# ATSAM4CMS32C_0 register map
Vendor: Atmel; Series: SAM4CM; File version: 0
CPU: CM4 r0p0, selectable endian, MPU, no FPU, 4 interrupt priority bits
Registers are 32-bit, read-write, reset 0x0 unless marked. A register's access mark holds for its fields unless they carry their own. Offsets are from the block's base; [hi:lo] are bit positions; {n}, {i} and the like mark numbered series.

## TRNG — True Random Number Generator
Base 0x40048000; register names take the prefix TRNG_
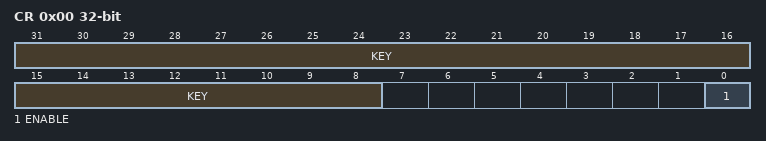
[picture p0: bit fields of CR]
0x00 CR wo reset not defined — Control Register
  [31:8] KEY — Security Key.
    0x524E47=PASSWD (Writing any other value in this field aborts the write operation.)
  [0] ENABLE — Enables the TRNG to provide random values
0x10 IER wo reset not defined — Interrupt Enable Register
  [0] DATRDY — Data Ready Interrupt Enable
0x14 IDR wo reset not defined — Interrupt Disable Register
  [0] DATRDY — Data Ready Interrupt Disable
0x18 IMR ro — Interrupt Mask Register
  [0] DATRDY — Data Ready Interrupt Mask
0x1C ISR ro — Interrupt Status Register
  [0] DATRDY — Data Ready
0x50 ODATA ro — Output Data Register
  [31:0] ODATA — Output Data

## IPC0 — Interprocessor Communication 0
Base 0x4004C000; register names take the prefix IPC0_
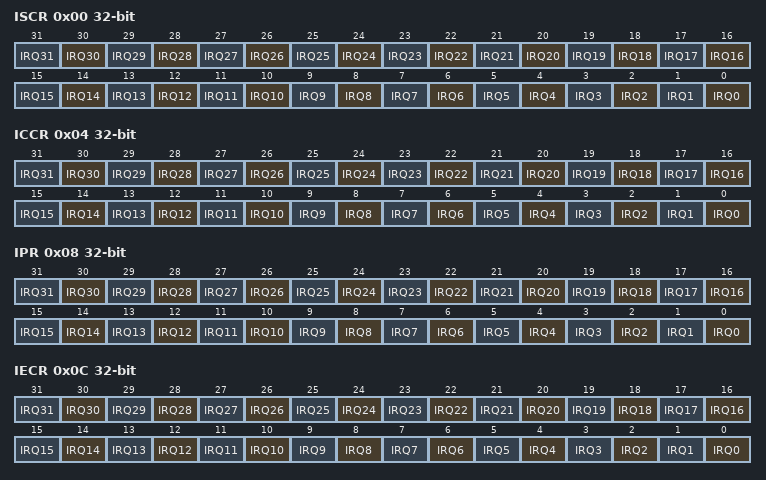
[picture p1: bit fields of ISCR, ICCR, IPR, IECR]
0x00 ISCR wo reset not defined — Interrupt Set Command Register
  [n] IRQ{n} (n=0..31) — Interrupt Set
0x04 ICCR wo reset not defined — Interrupt Clear Command Register
  [n] IRQ{n} (n=0..31) — Interrupt Clear
0x08 IPR ro — Interrupt Pending Register
  [n] IRQ{n} (n=0..31) — Interrupt Pending
0x0C IECR wo reset not defined — Interrupt Enable Command Register
  [n] IRQ{n} (n=0..31) — Interrupt Enable
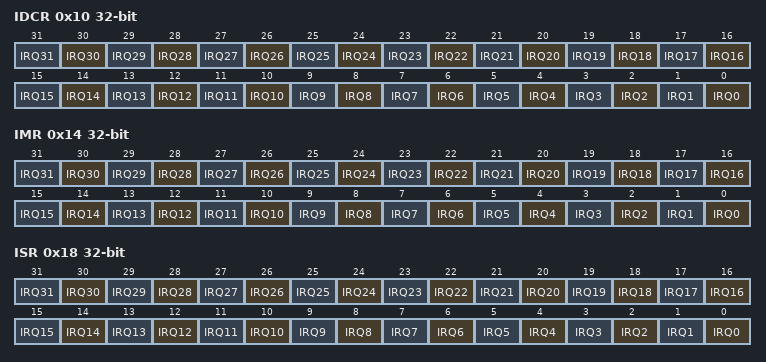
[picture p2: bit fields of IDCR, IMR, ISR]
0x10 IDCR wo reset not defined — Interrupt Disable Command Register
  [n] IRQ{n} (n=0..31) — Interrupt Disable
0x14 IMR ro — Interrupt Mask Register
  [n] IRQ{n} (n=0..31) — Interrupt Mask
0x18 ISR ro — Interrupt Status Register
  [n] IRQ{n} (n=0..31) — Current Interrupt Identifier

## IPC1 — Interprocessor Communication 1
Base 0x48014000; register names take the prefix IPC1_
Registers as IPC0.

## CMCC0 — Cortex M Cache Controller 0
Base 0x4007C000; register names take the prefix CMCC0_
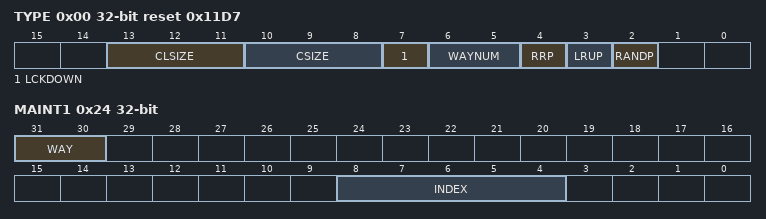
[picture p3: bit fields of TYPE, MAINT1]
0x00 TYPE ro reset 0x11D7 — Cache Type Register
  [13:11] CLSIZE — Cache Size
    0=CLSIZE_1KB (4 Bytes); 1=CLSIZE_2KB (8 Bytes); 2=CLSIZE_4KB (16 Bytes); 3=CLSIZE_8KB (32 Bytes)
  [10:8] CSIZE — Cache Size
    0=CSIZE_1KB (Cache Size 1 Kbytes); 1=CSIZE_2KB (Cache Size 2 Kbytes); 2=CSIZE_4KB (Cache Size 4 Kbytes); 3=CSIZE_8KB (Cache Size 8 Kbytes)
  [7] LCKDOWN — Lock Down Supported
  [6:5] WAYNUM — Number of Way
    0=DMAPPED (Direct Mapped Cache); 1=ARCH2WAY (2-WAY set associative); 2=ARCH4WAY (4-WAY set associative); 3=ARCH8WAY (8-WAY set associative)
  [4] RRP — Random Selection Policy Supported
  [3] LRUP — Least Recently Used Policy Supported
  [2] RANDP — Random Selection Policy Supported
0x08 CTRL wo — Cache Control Register
  [0] CEN — Cache Controller Enable
0x0C SR ro reset 0x1 — Cache Status Register
  [0] CSTS — Cache Controller Status
0x20 MAINT0 wo reset not defined — Cache Maintenance Register 0
  [0] INVALL — Cache Controller Invalidate All
0x24 MAINT1 wo reset not defined — Cache Maintenance Register 1
  [31:30] WAY — Invalidate Way
    {v}=Way {v} is selection for index invalidation (v=0..3)
  [8:4] INDEX — Invalidate Index
0x28 MCFG — Cache Monitor Configuration Register
  [1:0] MODE — Cache Controller Monitor Counter Mode
    0=CYCLE_COUNT (Cycle counter); 1=IHIT_COUNT (Instruction hit counter); 2=DHIT_COUNT (Data hit counter)
0x2C MEN — Cache Monitor Enable Register
  [0] MENABLE — Cache Controller Monitor Enable
0x30 MCTRL wo reset not defined — Cache Monitor Control Register
  [0] SWRST — Monitor
0x34 MSR ro — Cache Monitor Status Register
  [31:0] EVENT_CNT — Monitor Event Counter

## CMCC1 — Cortex M Cache Controller 1
Base 0x48018000; register names take the prefix CMCC1_
Registers as CMCC0.

## SMC0 — Static Memory Controller 0
Base 0x400E0000; register names take the prefix SMC0_
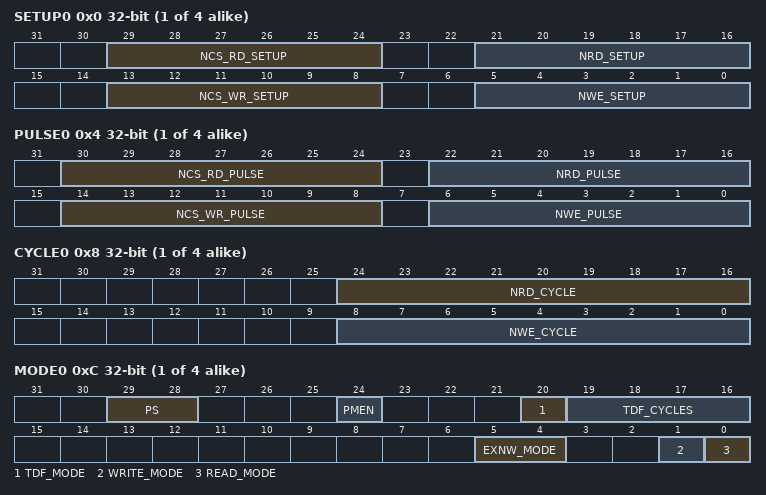
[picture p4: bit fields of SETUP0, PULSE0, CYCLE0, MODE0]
{0x0+0x10*i} SETUP{i} reset not defined (i=0..3) — SMC Setup Register (CS_number = {i})
  [29:24] NCS_RD_SETUP — NCS Setup Length in READ Access
  [21:16] NRD_SETUP — NRD Setup Length
  [13:8] NCS_WR_SETUP — NCS Setup Length in WRITE Access
  [5:0] NWE_SETUP — NWE Setup Length
{0x4+0x10*i} PULSE{i} reset not defined (i=0..3) — SMC Pulse Register (CS_number = {i})
  [30:24] NCS_RD_PULSE — NCS Pulse Length in READ Access
  [22:16] NRD_PULSE — NRD Pulse Length
  [14:8] NCS_WR_PULSE — NCS Pulse Length in WRITE Access
  [6:0] NWE_PULSE — NWE Pulse Length
{0x8+0x10*i} CYCLE{i} reset not defined (i=0..3) — SMC Cycle Register (CS_number = {i})
  [24:16] NRD_CYCLE — Total Read Cycle Length
  [8:0] NWE_CYCLE — Total Write Cycle Length
{0xC+0x10*i} MODE{i} reset not defined (i=0..3) — SMC Mode Register (CS_number = {i})
  [29:28] PS — Page Size
    0=4_BYTE (4-byte page); 1=8_BYTE (8-byte page); 2=16_BYTE (16-byte page); 3=32_BYTE (32-byte page)
  [24] PMEN — Page Mode Enabled
  [20] TDF_MODE — TDF Optimization
  [19:16] TDF_CYCLES — Data Float Time
  [5:4] EXNW_MODE — NWAIT Mode
    0=DISABLED; 2=FROZEN (Frozen Mode); 3=READY (Ready Mode)
  [1] WRITE_MODE
  [0] READ_MODE
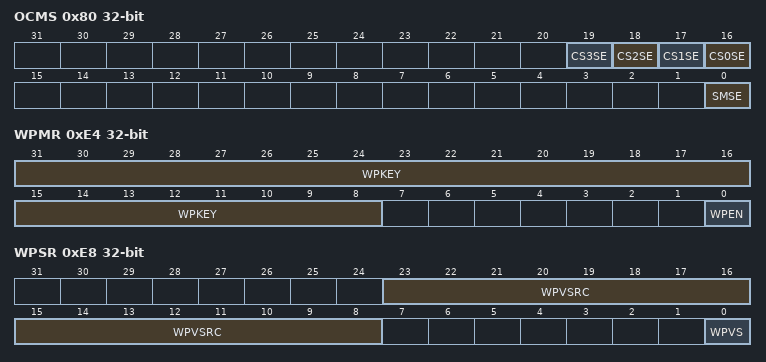
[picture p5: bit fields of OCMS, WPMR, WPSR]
0x80 OCMS — SMC OCMS MODE Register
  [n+16] CS{n}SE (n=0..3) — Chip Select (x = 0 to 3) Scrambling Enable
  [0] SMSE — Static Memory Controller Scrambling Enable
0x84 KEY1 wo — SMC OCMS KEY1 Register
  [31:0] KEY1 — Off Chip Memory Scrambling (OCMS) Key Part 1
0x88 KEY2 wo — SMC OCMS KEY2 Register
  [31:0] KEY2 — Off Chip Memory Scrambling (OCMS) Key Part 2
0xE4 WPMR — SMC Write Protect Mode Register
  [31:8] WPKEY — Write Protect KEY
  [0] WPEN — Write Protect Enable
0xE8 WPSR ro — SMC Write Protect Status Register
  [23:8] WPVSRC — Write Protect Violation Source
  [0] WPVS — Write Protect Enable

## SMC1 — Static Memory Controller 1
Base 0x4801C000; register names take the prefix SMC1_
Registers as SMC0.

## Notices in the file
SAM Software Package License
Copyright (c) 2015, Atmel Corporation
All rights reserved.
Redistribution and use in source and binary forms, with or without
modification, are permitted provided that the following condition is met:
- Redistributions of source code must retain the above copyright notice,
this list of conditions and the disclaimer below.
Atmel's name may not be used to endorse or promote products derived from
this software without specific prior written permission.
DISCLAIMER:  THIS SOFTWARE IS PROVIDED BY ATMEL "AS IS" AND ANY EXPRESS OR
IMPLIED WARRANTIES, INCLUDING, BUT NOT LIMITED TO, THE IMPLIED WARRANTIES OF
MERCHANTABILITY, FITNESS FOR A PARTICULAR PURPOSE AND NON-INFRINGEMENT ARE
DISCLAIMED. IN NO EVENT SHALL ATMEL BE LIABLE FOR ANY DIRECT, INDIRECT,
INCIDENTAL, SPECIAL, EXEMPLARY, OR CONSEQUENTIAL DAMAGES (INCLUDING, BUT NOT
LIMITED TO, PROCUREMENT OF SUBSTITUTE GOODS OR SERVICES; LOSS OF USE, DATA,
OR PROFITS; OR BUSINESS INTERRUPTION) HOWEVER CAUSED AND ON ANY THEORY OF
LIABILITY, WHETHER IN CONTRACT, STRICT LIABILITY, OR TORT (INCLUDING
NEGLIGENCE OR OTHERWISE) ARISING IN ANY WAY OUT OF THE USE OF THIS SOFTWARE,
EVEN IF ADVISED OF THE POSSIBILITY OF SUCH DAMAGE.
